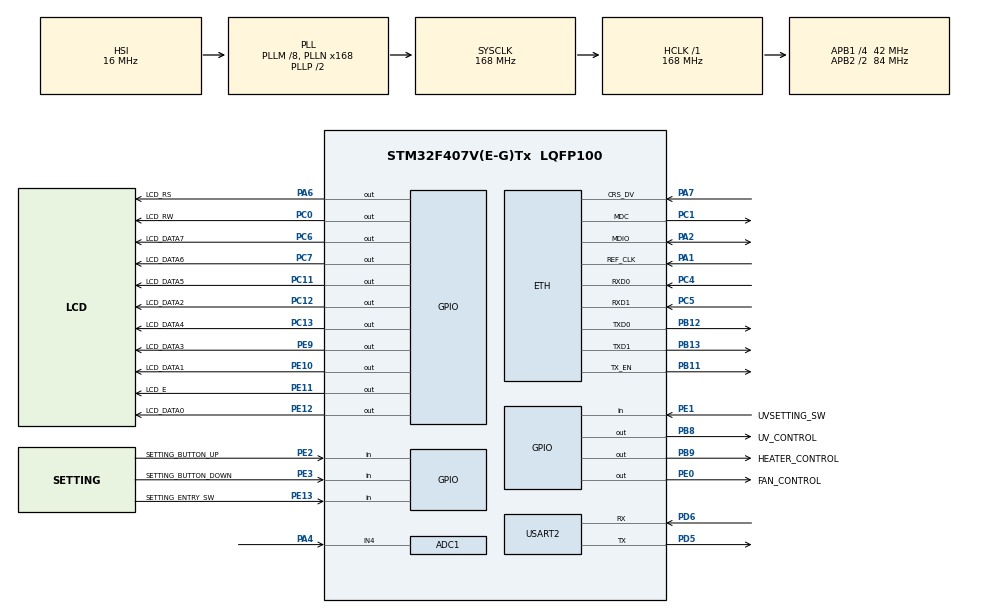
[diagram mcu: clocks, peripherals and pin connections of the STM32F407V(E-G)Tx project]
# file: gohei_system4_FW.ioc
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ADC1.Channel-14\#ChannelRegularConversion=ADC_CHANNEL_4
ADC1.Channel-8\#ChannelRegularConversion=ADC_CHANNEL_4
ADC1.ClockPrescaler=ADC_CLOCK_SYNC_PCLK_DIV4
ADC1.ContinuousConvMode=DISABLE
ADC1.DMAContinuousRequests=DISABLE
ADC1.DataAlign=ADC_DATAALIGN_RIGHT
ADC1.DiscontinuousConvMode=DISABLE
ADC1.EOCSelection=ADC_EOC_SINGLE_CONV
ADC1.EnableAnalogWatchDog=false
ADC1.ExternalTrigConv=ADC_SOFTWARE_START
ADC1.ExternalTrigConvEdge=ADC_EXTERNALTRIGCONVEDGE_NONE
ADC1.InjNumberOfConversion=0
ADC1.NbrOfConversion=1
ADC1.NbrOfConversionFlag=1
ADC1.Rank-14\#ChannelRegularConversion=1
ADC1.Rank-8\#ChannelRegularConversion=1
ADC1.Resolution=ADC_RESOLUTION_12B
ADC1.SamplingTime-14\#ChannelRegularConversion=ADC_SAMPLETIME_3CYCLES
ADC1.SamplingTime-8\#ChannelRegularConversion=ADC_SAMPLETIME_3CYCLES
ADC1.ScanConvMode=DISABLE
ADC1.master=1
ETH.MACAddr=00\:02\:F7\:F1\:D4\:EA
ETH.MediaInterface=ETH_MEDIA_INTERFACE_RMII
ETH.PHY_DUPLEX_STATUS=0x0010
ETH.PHY_Name_RMII=userPHY
ETH.PHY_SPEED_STATUS=0x0004
ETH.PHY_SR=0x1F
ETH.PHY_User_Name=LAN8720A
ETH.RxMode=ETH_RXINTERRUPT_MODE
FREERTOS.Tasks01=defaultTask,0,128,StartDefaultTask,Default,NULL,Dynamic,NULL,NULL
LWIP.LWIP_NETIF_LINK_CALLBACK=1
LWIP.LWIP_NETIF_STATUS_CALLBACK=1
LWIP.Version=v2.0.3_Cube
Mcu.Family=STM32F4
Mcu.Name=STM32F407V(E-G)Tx
Mcu.Package=LQFP100
NVIC.ETH_IRQn=true\:5\:0\:false\:false\:true\:true\:false
NVIC.PriorityGroup=NVIC_PRIORITYGROUP_4
NVIC.TIM1_UP_TIM10_IRQn=true\:0\:0\:false\:false\:true\:false\:false
NVIC.TimeBase=TIM1_UP_TIM10_IRQn
NVIC.TimeBaseIP=TIM10
PA1.Mode=RMII
PA1.Signal=ETH_REF_CLK
PA13.Mode=Serial_Wire
PA13.Signal=SYS_JTMS-SWDIO
PA14.Mode=Serial_Wire
PA14.Signal=SYS_JTCK-SWCLK
PA2.Mode=RMII
PA2.Signal=ETH_MDIO
PA4.Signal=ADCx_IN4
PA6.GPIO_Label=LCD_RS
PA6.Signal=GPIO_Output
PA7.Mode=RMII
PA7.Signal=ETH_CRS_DV
PB11.Mode=RMII
PB11.Signal=ETH_TX_EN
PB12.Mode=RMII
PB12.Signal=ETH_TXD0
PB13.Mode=RMII
PB13.Signal=ETH_TXD1
PB8.GPIO_Label=UV_CONTROL
PB8.Signal=GPIO_Output
PB9.GPIO_Label=HEATER_CONTROL
PB9.Signal=GPIO_Output
PC0.GPIO_Label=LCD_RW
PC0.Signal=GPIO_Output
PC1.Mode=RMII
PC1.Signal=ETH_MDC
PC11.GPIO_Label=LCD_DATA5
PC11.Signal=GPIO_Output
PC12.GPIO_Label=LCD_DATA2
PC12.Signal=GPIO_Output
PC13-ANTI_TAMP.GPIO_Label=LCD_DATA4
PC13-ANTI_TAMP.Signal=GPIO_Output
PC4.Mode=RMII
PC4.Signal=ETH_RXD0
PC5.Mode=RMII
PC5.Signal=ETH_RXD1
PC6.GPIO_Label=LCD_DATA7
PC6.Signal=GPIO_Output
PC7.GPIO_Label=LCD_DATA6
PC7.Signal=GPIO_Output
PD5.Mode=Asynchronous
PD5.Signal=USART2_TX
PD6.Mode=Asynchronous
PD6.Signal=USART2_RX
PE0.GPIO_Label=FAN_CONTROL
PE0.Signal=GPIO_Output
PE1.GPIO_Label=UVSETTING_SW
PE1.GPIO_PuPd=GPIO_PULLUP
PE1.Signal=GPIO_Input
PE10.GPIO_Label=LCD_DATA1
PE10.Signal=GPIO_Output
PE11.GPIO_Label=LCD_E
PE11.Signal=GPIO_Output
PE12.GPIO_Label=LCD_DATA0
PE12.Signal=GPIO_Output
PE13.GPIO_Label=SETTING_ENTRY_SW
PE13.GPIO_PuPd=GPIO_PULLUP
PE13.Signal=GPIO_Input
PE2.GPIO_Label=SETTING_BUTTON_UP
PE2.GPIO_PuPd=GPIO_PULLUP
PE2.Signal=GPIO_Input
PE3.GPIO_Label=SETTING_BUTTON_DOWN
PE3.GPIO_PuPd=GPIO_PULLUP
PE3.Signal=GPIO_Input
PE9.GPIO_Label=LCD_DATA3
PE9.Signal=GPIO_Output
ProjectManager.HeapSize=0x200
ProjectManager.StackSize=0x400
ProjectManager.TargetToolchain=Makefile
RCC.48MHZClocksFreq_Value=84000000
RCC.AHBFreq_Value=168000000
RCC.APB1CLKDivider=RCC_HCLK_DIV4
RCC.APB1Freq_Value=42000000
RCC.APB1TimFreq_Value=84000000
RCC.APB2CLKDivider=RCC_HCLK_DIV2
RCC.APB2Freq_Value=84000000
RCC.APB2TimFreq_Value=168000000
RCC.CortexFreq_Value=168000000
RCC.FLatency=FLASH_LATENCY_5
RCC.HCLKFreq_Value=168000000
RCC.HSE_VALUE=25000000
RCC.HSI_VALUE=16000000
RCC.LSE_VALUE=32768
RCC.PLLM=8
RCC.PLLN=168
RCC.SYSCLKFreq_VALUE=168000000
RCC.SYSCLKSource=RCC_SYSCLKSOURCE_PLLCLK
RCC.VCOOutputFreq_Value=336000000
SH.ADCx_IN4.0=ADC1_IN4,IN4
USART2.VirtualMode=VM_ASYNC
VP_FREERTOS_VS_ENABLE.Mode=Enabled
VP_LWIP_VS_Enabled.Mode=Enabled
VP_SYS_VS_tim10.Mode=TIM10
board=custom

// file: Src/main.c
/**
  ******************************************************************************
  * @file           : main.c
  * @brief          : Main program body
  ******************************************************************************
  * This notice applies to any and all portions of this file
  * that are not between comment pairs USER CODE BEGIN and
  * USER CODE END. Other portions of this file, whether
  * inserted by the user or by software development tools
  * are owned by their respective copyright owners.
  *
  * Copyright (c) 2020 STMicroelectronics International N.V.
  * All rights reserved.
  *
  * Redistribution and use in source and binary forms, with or without
  * modification, are permitted, provided that the following conditions are met:
  *
  * 1. Redistribution of source code must retain the above copyright notice,
  *    this list of conditions and the following disclaimer.
  * 2. Redistributions in binary form must reproduce the above copyright notice,
  *    this list of conditions and the following disclaimer in the documentation
  *    and/or other materials provided with the distribution.
  * 3. Neither the name of STMicroelectronics nor the names of other
  *    contributors to this software may be used to endorse or promote products
  *    derived from this software without specific written permission.
  * 4. This software, including modifications and/or derivative works of this
  *    software, must execute solely and exclusively on microcontroller or
  *    microprocessor devices manufactured by or for STMicroelectronics.
  * 5. Redistribution and use of this software other than as permitted under
  *    this license is void and will automatically terminate your rights under
  *    this license.
  *
  * THIS SOFTWARE IS PROVIDED BY STMICROELECTRONICS AND CONTRIBUTORS "AS IS"
  * AND ANY EXPRESS, IMPLIED OR STATUTORY WARRANTIES, INCLUDING, BUT NOT
  * LIMITED TO, THE IMPLIED WARRANTIES OF MERCHANTABILITY, FITNESS FOR A
  * PARTICULAR PURPOSE AND NON-INFRINGEMENT OF THIRD PARTY INTELLECTUAL PROPERTY
  * RIGHTS ARE DISCLAIMED TO THE FULLEST EXTENT PERMITTED BY LAW. IN NO EVENT
  * SHALL STMICROELECTRONICS OR CONTRIBUTORS BE LIABLE FOR ANY DIRECT, INDIRECT,
  * INCIDENTAL, SPECIAL, EXEMPLARY, OR CONSEQUENTIAL DAMAGES (INCLUDING, BUT NOT
  * LIMITED TO, PROCUREMENT OF SUBSTITUTE GOODS OR SERVICES; LOSS OF USE, DATA,
  * OR PROFITS; OR BUSINESS INTERRUPTION) HOWEVER CAUSED AND ON ANY THEORY OF
  * LIABILITY, WHETHER IN CONTRACT, STRICT LIABILITY, OR TORT (INCLUDING
  * NEGLIGENCE OR OTHERWISE) ARISING IN ANY WAY OUT OF THE USE OF THIS SOFTWARE,
  * EVEN IF ADVISED OF THE POSSIBILITY OF SUCH DAMAGE.
  *
  ******************************************************************************
  */
#include "main.h"
#include "stm32f4xx_hal.h"
#include "cmsis_os.h"
#include "adc.h"
#include "lwip.h"
#include "usart.h"
#include "gpio.h"

/* USER CODE BEGIN PV */
/* Private variables ---------------------------------------------------------*/

/* USER CODE END PV */

void SystemClock_Config(void);
void MX_FREERTOS_Init(void);

/* USER CODE BEGIN PFP */
/* Private function prototypes -----------------------------------------------*/

/* USER CODE END PFP */

int main(void)
{

  /* MCU Configuration----------------------------------------------------------*/

  /* Reset of all peripherals, Initializes the Flash interface and the Systick. */
  HAL_Init();

  /* Configure the system clock */
  SystemClock_Config();

  /* Initialize all configured peripherals */
  MX_GPIO_Init();
  MX_USART2_UART_Init();
  MX_ADC1_Init();

  /* Call init function for freertos objects (in freertos.c) */
  MX_FREERTOS_Init();

  /* Start scheduler */
  osKernelStart();

  /* We should never get here as control is now taken by the scheduler */

  /* Infinite loop */
  while (1)
  {

  }

}

void SystemClock_Config(void)
{

  RCC_OscInitTypeDef RCC_OscInitStruct;
  RCC_ClkInitTypeDef RCC_ClkInitStruct;

    /**Configure the main internal regulator output voltage
    */
  __HAL_RCC_PWR_CLK_ENABLE();

  __HAL_PWR_VOLTAGESCALING_CONFIG(PWR_REGULATOR_VOLTAGE_SCALE1);

    /**Initializes the CPU, AHB and APB busses clocks
    */
  RCC_OscInitStruct.OscillatorType = RCC_OSCILLATORTYPE_HSI;
  RCC_OscInitStruct.HSIState = RCC_HSI_ON;
  RCC_OscInitStruct.HSICalibrationValue = 16;
  RCC_OscInitStruct.PLL.PLLState = RCC_PLL_ON;
  RCC_OscInitStruct.PLL.PLLSource = RCC_PLLSOURCE_HSI;
  RCC_OscInitStruct.PLL.PLLM = 8;
  RCC_OscInitStruct.PLL.PLLN = 168;
  RCC_OscInitStruct.PLL.PLLP = RCC_PLLP_DIV2;
  RCC_OscInitStruct.PLL.PLLQ = 4;
  if (HAL_RCC_OscConfig(&RCC_OscInitStruct) != HAL_OK)
  {
    _Error_Handler(__FILE__, __LINE__);
  }

    /**Initializes the CPU, AHB and APB busses clocks
    */
  RCC_ClkInitStruct.ClockType = RCC_CLOCKTYPE_HCLK|RCC_CLOCKTYPE_SYSCLK
                              |RCC_CLOCKTYPE_PCLK1|RCC_CLOCKTYPE_PCLK2;
  RCC_ClkInitStruct.SYSCLKSource = RCC_SYSCLKSOURCE_PLLCLK;
  RCC_ClkInitStruct.AHBCLKDivider = RCC_SYSCLK_DIV1;
  RCC_ClkInitStruct.APB1CLKDivider = RCC_HCLK_DIV4;
  RCC_ClkInitStruct.APB2CLKDivider = RCC_HCLK_DIV2;

  if (HAL_RCC_ClockConfig(&RCC_ClkInitStruct, FLASH_LATENCY_5) != HAL_OK)
  {
    _Error_Handler(__FILE__, __LINE__);
  }

    /**Configure the Systick interrupt time
    */
  HAL_SYSTICK_Config(HAL_RCC_GetHCLKFreq()/1000);

    /**Configure the Systick
    */
  HAL_SYSTICK_CLKSourceConfig(SYSTICK_CLKSOURCE_HCLK);

  /* SysTick_IRQn interrupt configuration */
  HAL_NVIC_SetPriority(SysTick_IRQn, 15, 0);
}

void HAL_TIM_PeriodElapsedCallback(TIM_HandleTypeDef *htim)
{
  if (htim->Instance == TIM10) {
    HAL_IncTick();
  }
}

void _Error_Handler(char *file, int line)
{
  while(1)
  {
  }
}

/************************ (C) COPYRIGHT STMicroelectronics *****END OF FILE****/

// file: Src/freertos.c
/* USER CODE BEGIN Header */
/**
  ******************************************************************************
  * File Name          : freertos.c
  * Description        : Code for freertos applications
  ******************************************************************************
  * This notice applies to any and all portions of this file
  * that are not between comment pairs USER CODE BEGIN and
  * USER CODE END. Other portions of this file, whether
  * inserted by the user or by software development tools
  * are owned by their respective copyright owners.
  *
  * Copyright (c) 2019 STMicroelectronics International N.V.
  * All rights reserved.
  *
  * Redistribution and use in source and binary forms, with or without
  * modification, are permitted, provided that the following conditions are met:
  *
  * 1. Redistribution of source code must retain the above copyright notice,
  *    this list of conditions and the following disclaimer.
  * 2. Redistributions in binary form must reproduce the above copyright notice,
  *    this list of conditions and the following disclaimer in the documentation
  *    and/or other materials provided with the distribution.
  * 3. Neither the name of STMicroelectronics nor the names of other
  *    contributors to this software may be used to endorse or promote products
  *    derived from this software without specific written permission.
  * 4. This software, including modifications and/or derivative works of this
  *    software, must execute solely and exclusively on microcontroller or
  *    microprocessor devices manufactured by or for STMicroelectronics.
  * 5. Redistribution and use of this software other than as permitted under
  *    this license is void and will automatically terminate your rights under
  *    this license.
  *
  * THIS SOFTWARE IS PROVIDED BY STMICROELECTRONICS AND CONTRIBUTORS "AS IS"
  * AND ANY EXPRESS, IMPLIED OR STATUTORY WARRANTIES, INCLUDING, BUT NOT
  * LIMITED TO, THE IMPLIED WARRANTIES OF MERCHANTABILITY, FITNESS FOR A
  * PARTICULAR PURPOSE AND NON-INFRINGEMENT OF THIRD PARTY INTELLECTUAL PROPERTY
  * RIGHTS ARE DISCLAIMED TO THE FULLEST EXTENT PERMITTED BY LAW. IN NO EVENT
  * SHALL STMICROELECTRONICS OR CONTRIBUTORS BE LIABLE FOR ANY DIRECT, INDIRECT,
  * INCIDENTAL, SPECIAL, EXEMPLARY, OR CONSEQUENTIAL DAMAGES (INCLUDING, BUT NOT
  * LIMITED TO, PROCUREMENT OF SUBSTITUTE GOODS OR SERVICES; LOSS OF USE, DATA,
  * OR PROFITS; OR BUSINESS INTERRUPTION) HOWEVER CAUSED AND ON ANY THEORY OF
  * LIABILITY, WHETHER IN CONTRACT, STRICT LIABILITY, OR TORT (INCLUDING
  * NEGLIGENCE OR OTHERWISE) ARISING IN ANY WAY OUT OF THE USE OF THIS SOFTWARE,
  * EVEN IF ADVISED OF THE POSSIBILITY OF SUCH DAMAGE.
  *
  ******************************************************************************
  */
/* USER CODE END Header */

#include "FreeRTOS.h"
#include "task.h"
#include "main.h"
#include "cmsis_os.h"

/* USER CODE BEGIN Includes */
#include <stdbool.h>
#include "ServerAction.h"
#include "CageDriver.h"
/* USER CODE END Includes */

/* USER CODE BEGIN Variables */
bool isMXInitFinished = false;

/* USER CODE END Variables */
osThreadId defaultTaskHandle;

void StartDefaultTask(void const * argument);

extern void MX_LWIP_Init(void);
void MX_FREERTOS_Init(void); /* (MISRA C 2004 rule 8.1) */

void MX_FREERTOS_Init(void) {

  /* Create the thread(s) */
  /* definition and creation of defaultTask */
  osThreadDef(defaultTask, StartDefaultTask, osPriorityNormal, 0, 128);
  defaultTaskHandle = osThreadCreate(osThread(defaultTask), NULL);

  /* USER CODE BEGIN RTOS_THREADS */
  /* add threads, ... */
  osThreadDef(serverActionTask, ServerThreadFunc, osPriorityNormal, 0, 1024);
  osThreadId serverThreadId = osThreadCreate(osThread(serverActionTask), NULL);
  SetServerThreadID(serverThreadId);

  osThreadDef(cageTask, CageDriveThread, osPriorityNormal, 0, 512);
  osThreadCreate(osThread(cageTask), NULL);
  /* USER CODE END RTOS_THREADS */

}

void StartDefaultTask(void const * argument)
{
  /* init code for LWIP */
  MX_LWIP_Init();

  /* USER CODE BEGIN StartDefaultTask */
  isMXInitFinished = true;
  /* Infinite loop */
  for(;;)
  {

    osDelay(1);
  }
  /* USER CODE END StartDefaultTask */
}

/* USER CODE BEGIN Application */
bool IsMXInitFinished()
{
  return isMXInitFinished;
}

/* USER CODE END Application */

/************************ (C) COPYRIGHT STMicroelectronics *****END OF FILE****/
